# CM4 register map
CPU: CM4 r0p1, selectable endian, MPU, FPU, 4 interrupt priority bits
Registers are 32-bit, read-write, reset 0x0 unless marked. A register's access mark holds for its fields unless they carry their own. Offsets are from the block's base; [hi:lo] are bit positions; {n}, {i} and the like mark numbered series.

## SCB — System Control Block
Base 0xE000ED00
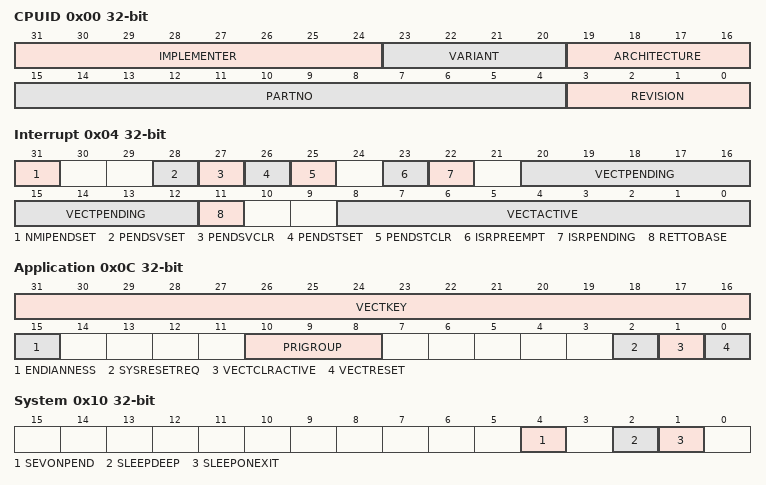
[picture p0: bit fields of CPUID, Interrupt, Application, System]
0x00 CPUID Base Register ro — Provides identification information for the processor
  [31:24] IMPLEMENTER — Implementer code assigned by ARM
  [23:20] VARIANT — IMPLEMENTATION DEFINED variant number
  [19:16] ARCHITECTURE — Reads as 0xF
  [15:4] PARTNO — IMPLEMENTATION DEFINED part number
  [3:0] REVISION — IMPLEMENTATION DEFINED revision number
0x04 Interrupt Control and State Register — Provides software control of the NMI, PendSV, and SysTick exceptions, and provides interrupt status information
  [31] NMIPENDSET write-1-sets — On writes, makes the NMI exception active
    0=cleared (On writes, has no effect. On reads, NMI is inactive); 1=set_pending (On writes, make the NMI exception active. On reads, NMI is active)
  [28] PENDSVSET write-1-sets — On writes, sets the PendSV exception as pending
    0=cleared (On writes, has no effect. On reads, PendSV is not pending); 1=set_pending (On writes, make PendSV exception pending. On reads, PendSV is pending)
  [27] PENDSVCLR write-1-sets — Removes the pending status of the PendSV exception
    0=No effect; 1=clear (Remove pending status)
  [26] PENDSTSET write-1-sets — On writes, sets the SysTick exception as pending
    0=cleared (On writes, has no effect. On reads, SysTick is not pending); 1=set_pending (On writes, make SysTick exception pending. On reads, SysTick is pending)
  [25] PENDSTCLR write-1-sets — Removes the pending status of the SysTick exception
    0=No effect; 1=clear (Remove pending status)
  [23] ISRPREEMPT — Indicates whether a pending exception will be serviced on exit from debug halt state
    0=Will not service; 1=Will service a pending exception
  [22] ISRPENDING — Indicates whether an external interrupt, generated by the NVIC, is pending
    0=No external interrupt pending; 1=External interrupt pending
  [20:12] VECTPENDING — The exception number of the highest priority pending and enabled interrupt
  [11] RETTOBASE — In Handler mode, indicates whether there is an active exception other than the exception indicated by the current value of the IPSR
    0=There is an active exception other than the exception shown by IPSR; 1=There is no active exception other than any exception shown by IPSR
  [8:0] VECTACTIVE — The exception number of the current executing exception
0x08 Vector Table Offset Register — Holds the vector table address
  [31:7] TBLOFF — Bits[31:7] of the vector table address
0x0C Application Interrupt and Reset Control Register — Sets or returns interrupt control data
  [31:16] VECTKEY range 0x05FA..0x05FA — Vector Key. The value 0x05FA must be written to this register.
    0=Do not request a reset; 0x5FA=Request reset
  [15] ENDIANNESS — Indicates the memory system endianness
    0=Little endian; 1=Big endian
  [10:8] PRIGROUP — Priority grouping, indicates the binary point position
  [2] SYSRESETREQ — System Reset Request
    0=Do not request a reset; 1=Request reset
  [1] VECTCLRACTIVE — Writing 1 to this bit clears all active state information for fixed and configurable exceptions
  [0] VECTRESET — Writing 1 to this bit causes a local system reset
0x10 System Control Register — Sets or returns system control data
  [4] SEVONPEND — Determines whether an interrupt transition from inactive state to pending state is a wakeup event
    0=Transitions from inactive to pending are not wakeup events; 1=Transitions from inactive to pending are wakeup events
  [2] SLEEPDEEP — Provides a qualifying hint indicating that waking from sleep might take longer
    0=Selected sleep state is not deep sleep; 1=Selected sleep state is deep sleep
  [1] SLEEPONEXIT — Determines whether, on an exit from an ISR that returns to the base level of execution priority, the processor enters a sleep state
    0=Do not enter sleep state; 1=Enter sleep state
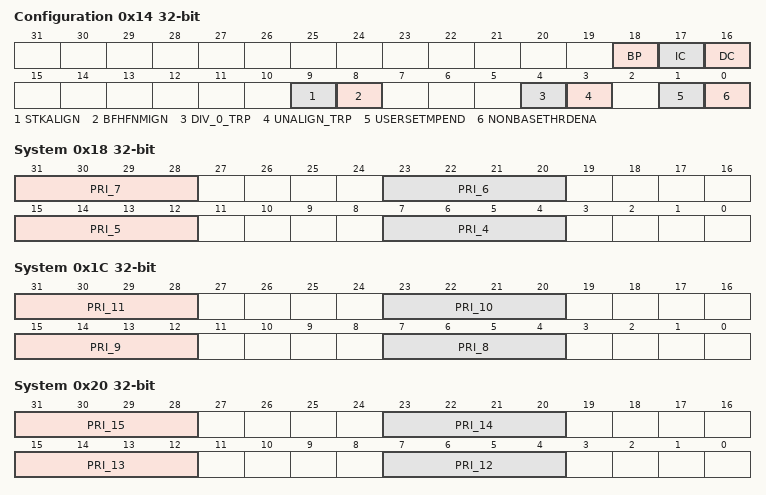
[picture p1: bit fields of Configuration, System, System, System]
0x14 Configuration and Control Register — Sets or returns configuration and control data, and provides control over caching and branch prediction
  [18] BP — Branch prediction enable bit
    0=Program flow prediction disabled; 1=Program flow prediction enabled
  [17] IC — Instruction cache enable bit
    0=Instruction caches disabled; 1=Instruction caches enabled
  [16] DC — Cache enable bit
    0=Data and unified caches disabled; 1=Data and unified caches enabled
  [9] STKALIGN — Determines whether the exception entry sequence guarantees 8-byte stack frame alignment, adjusting the SP if necessary before saving state
    0=Guaranteed SP alignment is 4-byte, no SP adjustment is performed; 1=8-byte alignment guaranteed, SP adjusted if necessary
  [8] BFHFNMIGN — Determines the effect of precise data access faults on handlers running at priority -1 or priority -2
    0=Precise data access fault causes a lockup; 1=Handler ignores the fault
  [4] DIV_0_TRP — Controls the trap on divide by 0
    0=Trapping disabled; 1=Trapping enabled
  [3] UNALIGN_TRP — Controls the trapping of unaligned word or halfword accesses
    0=Trapping disabled; 1=Trapping enabled
  [1] USERSETMPEND — Controls whether unprivileged software can access the STIR
    0=Unprivileged software cannot access the STIR; 1=Unprivileged software can access the STIR
  [0] NONBASETHRDENA — Controls whether the processor can enter Thread mode with exceptions active
    0=Any attempt to enter Thread mode with exceptions active faults; 1=The processor can enter Thread mode with exceptions active because of a controlled return value
0x18 System Handler Priority Register 1 — Sets or returns priority for system handlers 4-7
  [31:28] PRI_7 — Reserved for priority of system handler 7
  [23:20] PRI_6 — Priority of system handler 6, UsageFault
  [15:12] PRI_5 — Priority of system handler 5, BusFault
  [7:4] PRI_4 — Priority of system handler 4, MemManage
0x1C System Handler Priority Register 2 — Sets or returns priority for system handlers 8-11
  [31:28] PRI_11 — Priority of system handler 11, SVCall
  [23:20] PRI_10 — Reserved for priority of system handler 10
  [15:12] PRI_9 — Reserved for priority of system handler 9
  [7:4] PRI_8 — Reserved for priority of system handler 8
0x20 System Handler Priority Register 3 — Sets or returns priority for system handlers 12-15
  [31:28] PRI_15 — Priority of system handler 15, SysTick
  [23:20] PRI_14 — Priority of system handler 14, PendSV
  [15:12] PRI_13 — Reserved for priority of system handler 13
  [7:4] PRI_12 — Priority of system handler 12, DebugMonitor
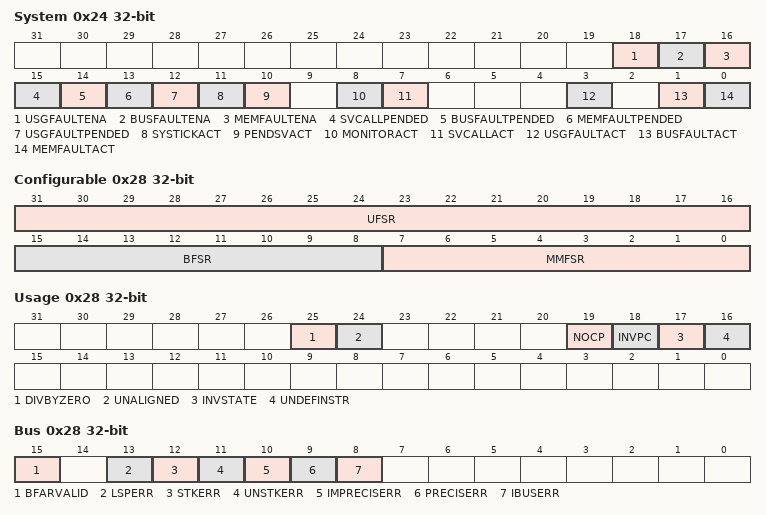
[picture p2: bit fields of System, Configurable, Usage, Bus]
0x24 System Handler Control and State Register — Controls and provides the active and pending status of system exceptions
  [18] USGFAULTENA — UsageFault exception enable
    0=Disable UsageFault; 1=Enable UsageFault
  [17] BUSFAULTENA — BusFault exception enable
    0=Disable BusFault; 1=Enable BusFault
  [16] MEMFAULTENA — MemManage exception enable
    0=Disable MemManage fault; 1=Enable MemManage fault
  [15] SVCALLPENDED — SVCall exception pended state
    0=SVCall execption is not pending; 1=SVCall execption is pending
  [14] BUSFAULTPENDED — BusFault exception pended state
    0=BusFault execption is not pending; 1=BusFault execption is pending
  [13] MEMFAULTPENDED — MemManage exception pended state
    0=MemManage exception is not pending; 1=MemManage exception is pending
  [12] USGFAULTPENDED — UsageFault exception pended state
    0=UsageFault exception is not pending; 1=UsageFault exception is pending
  [11] SYSTICKACT — SysTick exception active state
    0=SysTick exception is not active; 1=SysTick exception is active
  [10] PENDSVACT — PendSV exception active state
    0=PendSV exception is not active; 1=PendSV exception is active
  [8] MONITORACT — DebugMonitor exception active state
    0=DebugMonitor exception not active; 1=DebugMonitor exception is active
  [7] SVCALLACT — SVCall exception active state
    0=SVCall exception is not active; 1=SVCall exception is active
  [3] USGFAULTACT — UsageFault exception active state
    0=UsageFault exception is not active; 1=UsageFault exception is active
  [1] BUSFAULTACT — BusFault exception active state
    0=BusFault exception is not active; 1=BusFault exception is active
  [0] MEMFAULTACT — MemManage exception active state
    0=MemManage exception is not active; 1=MemManage exception is active
0x28 Configurable Fault Status Register — Contains the three Configurable Fault Status Registers
  [31:16] UFSR — Provides information on UsageFault exceptions
  [15:8] BFSR — Provides information on BusFault exceptions
  [7:0] MMFSR — Provides information on MemManage exceptions
0x28 Usage Fault Status Register — Provides information on UsageFault exceptions
  [all] fields
    0=Error has not occurred; 1=Error has occurred
  [25] DIVBYZERO — Divide by zero flag. Indicates whether an integer division by zero error has occurred
  [24] UNALIGNED — Unaligned access flag. Indicates whether an unaligned access error has occurred
  [19] NOCP — No coprocessor flag. Indicates whether a coprocessor disabled or not present error has occurred
  [18] INVPC — Invalid PC flag. Indicates whether an integrity check error has occurred
  [17] INVSTATE — Invalid state flag. Indicates whether an EPSR.T or EPSR.IT validity error has occurred
  [16] UNDEFINSTR — Undefined instruction flag. Indicates whether an undefined instruction error has occurred
0x28 Bus Fault Status Register — Provides information on BusFault exceptions
  [15] BFARVALID — BFAR valid. Indicates validity of the contents of the BFAR register
    0=BFAR content not valid; 1=BFAR content valid
  [13] LSPERR — Lazy state preservation error. Records whether a BusFault occurred during FP lazy state preservation
    0=No BusFault occurred during FP lazy state preservation; 1=BusFault occurred during FP lazy state preservation
  [12] STKERR — Stack error. Records whether a derived BusFault occurred during exception entry stacking
    0=No derived BusFault occurred; 1=Derived BusFault occurred during exception entry
  [11] UNSTKERR — Unstack error. Records whether a derived BusFault occurred during exception return unstacking
    0=No derived BusFault occurred; 1=Derived BusFault occurred during exception return
  [10] IMPRECISERR — Imprecise error. Records whether an imprecise data access error has occurred
    0=No imprecise data access error has occurred; 1=Imprecise data access error has occurred
  [9] PRECISERR — Precise error. Records whether a precise data access error has occurred
    0=No precise data access error has occurred; 1=Precise data access error has occurred
  [8] IBUSERR — Instruction bus error. Records whether a BusFault on an instruction prefetch has occurred
    0=No BusFault on instruction prefetch has occurred; 1=A BusFault on an instruction prefetch has occurred
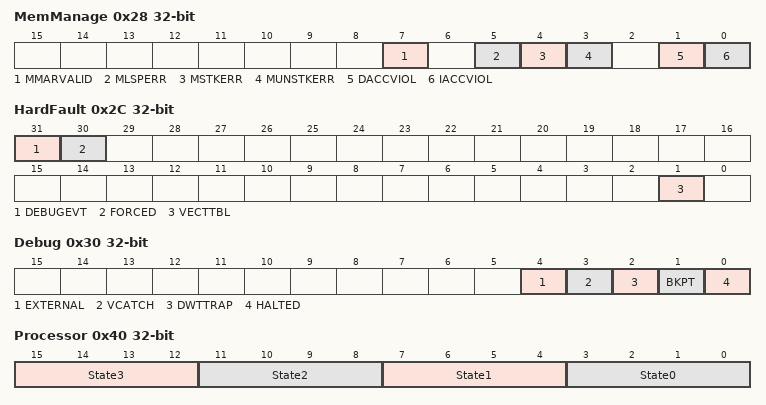
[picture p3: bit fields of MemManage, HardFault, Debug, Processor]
0x28 MemManage Fault Status Register — Provides information on MemManage exceptions
  [7] MMARVALID — MMFAR valid flag. Indicates validity of the MMFAR register
    0=MMFAR content not valid; 1=MMFAR content valid
  [5] MLSPERR — MemManage lazy state preservation error flag. Records whether a MemManage fault occurred during FP lazy state preservation
    0=No MemManage occurred during FP lazy state preservation; 1=MemManage occurred during FP lazy state preservation
  [4] MSTKERR — MemManage stacking error flag. Records whether a derived MemManage fault occurred during exception entry stacking
    0=No derived MemManage occurred; 1=Derived MemManage occurred during exception entry
  [3] MUNSTKERR — MemManage unstacking error flag. Records whether a derived MemManage fault occurred during exception return unstacking
    0=No derived MemManage fault occurred; 1=Derived MemManage fault occurred during exception return
  [1] DACCVIOL — Data access violation flag. Records whether a data access violation has occurred
    0=No MemManage fault on data access has occurred; 1=MemManage fault on data access has occurred
  [0] IACCVIOL — Instruction access violation. Records whether an instruction related memory access violation has occurred
    0=No MemManage fault on instruction access has occurred; 1=MemManage fault on instruction access has occurred
0x2C HardFault Status Register — Shows the cause of any HardFault
  [31] DEBUGEVT — Indicates that a debug event has occurred
    0=No debug event has occurred; 1=Debug event has occurred. The Debug Fault Status Register has been updated
  [30] FORCED — Indicates that a fault with configurable priority has been escalated to a HardFault exception, because it could not be made active, because of priority or because it was disabled
    0=No priority escalation has occurred; 1=Processor has escalated a configurable-priority exception to HardFault
  [1] VECTTBL — Indicates when a fault has occurred because of a vector table read error on exception processing
    0=No vector table read fault has occurred; 1=Vector table read fault has occurred
0x30 Debug Fault Status Register — Shows which debug event occurred
  [all] fields
    0=Debug event has not occurred; 1=Debug event has occurred
  [4] EXTERNAL — External event. Indicates whether an external debug request has occurred
  [3] VCATCH — Vector Catch event. Indicates whether a Vector catch debug event has occurred
  [2] DWTTRAP — Watchpoint event. Indicates whether a Watchpoint debug event has occurred
  [1] BKPT — Breakpoint event. Indicates whether a breakpoint debug event has occurred
  [0] HALTED — Halt or step event. Indicates that a Halt request debug event or Step debug event has occurred
0x34 MemManage Fault Address Register — Shows the address of the memory location that caused an MPU fault
  [31:0] ADDRESS — Address of the memory location that caused the MemManage fault, valid while MMFSR.MMARVALID is set
0x38 BusFault Address Register — Shows the address associated with a precise data access BusFault
  [31:0] ADDRESS — Address of the precise data access BusFault, valid while BFSR.BFARVALID is set
0x3C Auxiliary Fault Status Register — Provides implementation-specific fault status information and control
0x40 Processor Feature Register 0 ro — Gives top-level information about the instruction sets supported by the processor
  [15:12] State3 — ARMv7-M reserved
  [11:8] State2 — ARMv7-M reserved
  [7:4] State1 — Thumb instruction set support
    3=Support for Thumb encoding including Thumb-2 technology, with all basic 16-bit and 32-bit instructions
  [3:0] State0 — ARM instruction set support
    0=The processor does not support the ARM instruction set; 1=ARMv7-M reserved
0x44 Processor Feature Register 1 ro — Gives top-level information about the instruction sets supported by the processor
  [11:8] M profile programmers model
    0=ARMv7-M reserved; 2=Two-stack programmers model supported
0x48 Debug Feature Register 0 ro — Gives top-level information about the debug system used in the processor
  [23:20] Debug model, M profile — Support for memory-mapped debug model for M profile processors
    0=Not supported; 1=Support for M profile Debug architecture, with memory-mapped access
0x4C Auxiliary Feature Register 0 ro — Gives information about the IMPLEMENTATION DEFINED features of a processor implementation
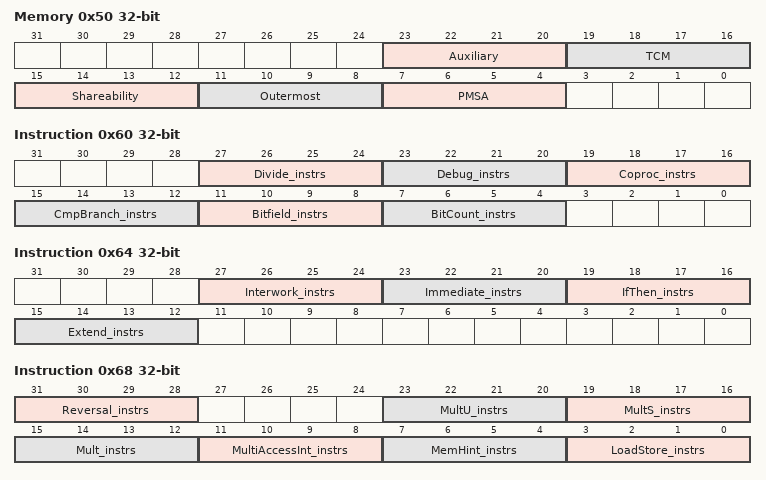
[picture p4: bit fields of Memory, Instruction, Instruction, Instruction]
0x50 Memory Model Feature Register 0 ro — Gives information about the implemented memory model and memory management support
  [23:20] Auxiliary registers — Indicates the support for Auxiliary registers
    0=Not supported; 1=Support for Auxiliary Control Register only; 2=ARMv7-M reserved
  [19:16] TCM support — Indicates the support for Tightly Coupled Memory (TCM)
    0=No tightly coupled memories implemented; 1=Tightly coupled memories implemented with IMPLEMENTATION DEFINED control; 2=ARMv7-M reserved
  [15:12] Shareability levels — Indicates the number of shareability levels implemented
    0=One level of shareability implemented; 1=ARMv7-M reserved
  [11:8] Outermost shareability — Indicates the outermost shareability domain implemented
    0=Implemented as Non-cacheable; 1=ARMv7-M reserved; 15=Shareability ignored
  [7:4] PMSA support — Indicates support for a PMSA
    0=Not supported; 3=PMSAv7, providing support for a base region and subregions
0x54 Memory Model Feature Register 1 ro — Gives information about the implemented memory model and memory management support
0x58 Memory Model Feature Register 2 ro — Gives information about the implemented memory model and memory management support
  [27:24] WFI stall — Indicates the support for Wait For Interrupt (WFI) stalling
    0=Not supported; 1=Support for WFI stalling
0x5C Memory Model Feature Register 3 ro — Gives information about the implemented memory model and memory management support
0x60 Instruction Set Attribute Register 0 ro — Gives information about the instruction sets implemented by the processor
  [27:24] Divide_instrs — Indicates the supported Divide instructions
    0=None supported, ARMv7-M reserved; 1=Adds support for the SDIV and UDIV instructions
  [23:20] Debug_instrs — Indicates the supported Debug instructions
    0=None supported, ARMv7-M reserved; 1=Adds support for the BKPT instruction
  [19:16] Coproc_instrs — Indicates the supported Coprocessor instructions
    0=None supported, except for separately attributed architectures, for example the Floating-point extension; 1=Adds support for generic CDP, LDC, MCR, MRC, and STC instructions; 2=As for 1, and adds support for generic CDP2, LDC2, MCR2, MRC2, and STC2 instructions; 3=As for 2, and adds support for generic MCRR and MRRC instructions, 4 As for 3, and adds support for generic MCRR2 and MRRC2 inst
  [15:12] CmpBranch_instrs — Indicates the supported combined Compare and Branch instructions
    0=None supported, ARMv7-M reserved; 1=Adds support for the CBNZ and CBZ instructions
  [11:8] Bitfield_instrs — Indicates the supported BitField instructions
    0=None supported, ARMv7-M reserved; 1=Adds support for the BFC, BFI, SBFX, and UBFX instructions
  [7:4] BitCount_instrs — Indicates the supported Bit Counting instructions
    0=None supported, ARMv7-M reserved; 1=Adds support for the CLZ instruction
0x64 Instruction Set Attribute Register 1 ro — Gives information about the instruction sets implemented by the processor
  [27:24] Interwork_instrs — Indicates the supported Interworking instructions
    0=None supported, ARMv7-M reserved; 1=Adds support for the BX instruction, and the T bit in the PSR; 2=As for 1, and adds support for the BLX instruction, and PC loads have BX-like behavior; 3=ARMv7-M reserved
  [23:20] Immediate_instrs — Indicates the support for data-processing instructions with long immediates
    0=None supported, ARMv7-M reserved; 1=Adds support for the ADDW, MOVW, MOVT, and SUBW instructions
  [19:16] IfThen_instrs — Indicates the supported IfThen instructions
    0=None supported, ARMv7-M reserved; 1=Adds support for the IT instructions, and for the IT bits in the PSRs
  [15:12] Extend_instrs — Indicates the supported Extend instructions
    0=None supported, ARMv7-M reserved; 1=Adds support for the SXTB, SXTH, UXTB, and UXTH instructions; 2=As for 1, and adds support for the SXTAB, SXTAB16, SXTAH, SXTB16, UXTAB, UXTAB16, UXTAH, and UXTB16 instructions
0x68 Instruction Set Attribute Register 2 ro — Gives information about the instruction sets implemented by the processor
  [31:28] Reversal_instrs — Indicates the supported Reversal instructions
    0=None supported, ARMv7-M reserved; 1=Adds support for the REV, REV16, and REVSH instructions, ARMv7-M reserved; 2=As for 1, and adds support for the RBIT instruction
  [23:20] MultU_instrs — Indicates the supported advanced unsigned Multiply instructions
    0=None supported, ARMv7-M reserved; 1=Adds support for the UMULL and UMLAL instructions; 2=As for 1, and adds support for the UMAAL instruction
  [19:16] MultS_instrs — Indicates the supported advanced signed Multiply instructions
    0=None supported, ARMv7-M reserved; 1=Adds support for the SMULL and SMLAL instructions; 2=As for 1, and adds support for the SMLABB, SMLABT, SMLALBB, SMLALBT, SMLALTB, SMLALTT, SMLATB, SMLATT, SMLAWB, SMLAWT, SMULBB, S; 3=As for 2, and adds support for the SMLAD, SMLADX, SMLALD, SMLALDX, SMLSD, SMLSDX, SMLSLD, SMLSLDX, SMMLA, SMMLAR, SMMLS, SMMLSR,
  [15:12] Mult_instrs — Indicates the supported additional Multiply instructions
    0=None supported. This means only MUL is supported. ARMv7-M reserved; 1=Adds support for the MLA instruction, ARMv7-M reserved; 2=As for 1, and adds support for the MLS instruction
  [11:8] MultiAccessInt_instrs — Indicates the support for multi-access interruptible instructions
    0=None supported. This means the LDM and STM instructions are not interruptible; 1=LDM and STM instructions are restartable; 2=LDM and STM instructions are continuable
  [7:4] MemHint_instrs — Indicates the supported Memory Hint instructions
    0=None supported, ARMv7-M reserved; 2=Adds support for the PLD instruction; 3=As for 1 or 2, and adds support for the PLI instruction
  [3:0] LoadStore_instrs — Indicates the supported additional load and store instructions
    0=None supported, ARMv7-M reserved; 1=Adds support for the LDRD and STRD instructions
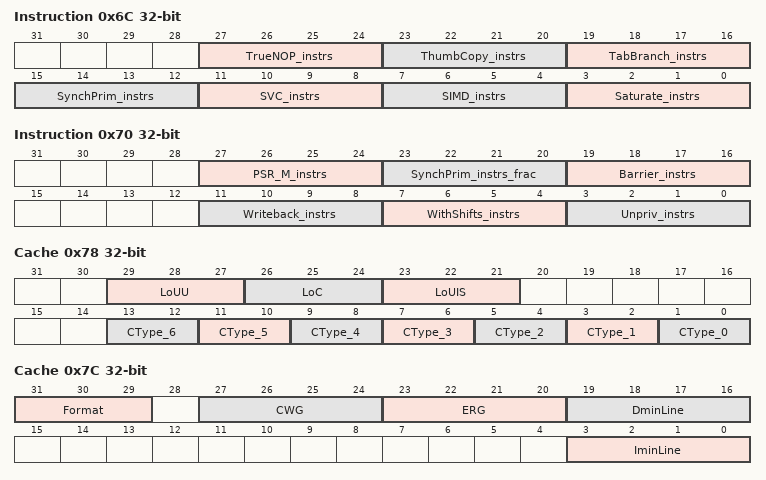
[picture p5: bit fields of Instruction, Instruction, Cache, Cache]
0x6C Instruction Set Attribute Register 3 ro — Gives information about the instruction sets implemented by the processor
  [27:24] TrueNOP_instrs — Indicates the support for a true NOP instruction
    0=None supported, ARMv7-M reserved; 1=Adds support for the true NOP instruction
  [23:20] ThumbCopy_instrs — Indicates the supported non flag-setting MOV instructions
    0=None supported, ARMv7-M reserved; 1=Adds support for encoding T1 of the MOV (register) instruction copying from a low register to a low register
  [19:16] TabBranch_instrs — Indicates the supported Table Branch instructions
    0=None supported, ARMv7-M reserved; 1=Adds support for the TBB and TBH instructions
  [15:12] SynchPrim_instrs — Must be interpreted with the ID_ISAR4
  [11:8] SVC_instrs — Indicates the supported SVC instructions
    0=None supported, ARMv7-M reserved; 1=Adds support for the SVC instruction
  [7:4] SIMD_instrs — Indicates the supported SIMD instructions
    0=None supported, ARMv7-M reserved; 1=Adds support for the SSAT and USAT instructions, and for the Q bit in the PSRs; 3=As for 1, and adds support for the PKHBT, PKHTB, QADD16, QADD8, QASX, QSUB16, QSUB8, QSAX, SADD16, SADD8, SASX, SEL, SHADD16, SH
  [3:0] Saturate_instrs — Indicates the supported Saturate instructions
    0=None supported; 1=Adds support for the QADD, QDADD, QDSUB, and QSUB instructions, and for the Q bit in the PSRs
0x70 Instruction Set Attribute Register 4 ro — Gives information about the instruction sets implemented by the processor
  [27:24] PSR_M_instrs — Indicates the supported M profile instructions to modify the PSRs
    0=None supported, ARMv7-M reserved; 1=Adds support for the M-profile forms of the CPS, MRS, and MSR instructions, to access the PSRs
  [23:20] SynchPrim_instrs_frac — Must be interpreted with the ID_ISAR3
  [19:16] Barrier_instrs — Indicates the supported Barrier instructions
    0=None supported, ARMv7-M reserved; 1=Adds support for the DMB, DSB, and ISB barrier instructions
  [11:8] Writeback_instrs — Indicates the support for Writeback addressing modes
    0=Basic support; 1=Adds support for all of the writeback addressing modes defined in the ARMv7-M architecture
  [7:4] WithShifts_instrs — Indicates the support for instructions with shifts
    0=Nonzero shifts supported only in MOV and shift instructions; 1=Adds support for shifts of loads and stores over the range LSL 0-3; 3=As for 1, and adds support for other constant shift options, on loads, stores, and other instructions; 4=ARMv7-M reserved
  [3:0] Unpriv_instrs — Indicates the supported unprivileged instructions
    0=None supported, ARMv7-M reserved; 1=Adds support for the LDRBT, LDRT, STRBT, and STRT instructions; 2=As for 1, and adds support for the LDRHT, LDRSBT, LDRSHT, and STRHT instructions
0x78 Cache Level ID Register ro — The CLIDR identifies: ? The type of cache, or caches, implemented at each level, up to a maximum of seven levels
  [29:27] LoUU — Level of Unification Uniprocessor for the cache hierarchy
  [26:24] LoC — Level of Coherency for the cache hierarchy
  [23:21] LoUIS — Level of Unification Inner Shareable for the cache hierarchy
  [2n+1:2n] CType_{n} (n=0..6) — Indicates the type of cache implemented at each level
    0=No cache; 1=Instruction cache only; 2=Data cache only; 3=Separate instruction and data caches; 4=Unified cache
0x7C Cache Type Register ro — The CTR provides information about the architecture of the caches
  [31:29] Format — Indicates the implemented CTR format
    4=ARMv7 format. This is the format described in this section
  [27:24] CWG — Cache Write-back Granule
  [23:20] ERG — Exclusives Reservation Granule
  [19:16] DminLine — Log2 of the number of words in the smallest cache line of all the data caches and unified caches that are controlled by the processor
  [3:0] IminLine — Log2 of the number of words in the smallest cache line of all the instruction caches that are controlled by the processor
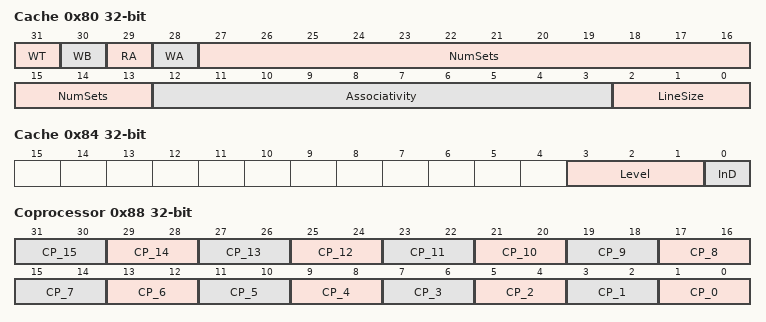
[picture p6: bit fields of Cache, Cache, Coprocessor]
0x80 Cache Size ID Registers ro — The CCSIDR provides information about the architecture of the caches
  [31] WT — Indicates whether the cache level supports write-through
  [30] WB — Indicates whether the cache level supports write-back
  [29] RA — Indicates whether the cache level supports read-allocation
  [28] WA — Indicates whether the cache level supports write-allocation
  [27:13] NumSets — (Number of sets in cache)-1, therefore a value of 0 indicates 1 set in the cache
  [12:3] Associativity — (Associativity of cache)-1, therefore a value of 0 indicates an associativity of 1
  [2:0] LineSize — (Log2(Number of words in cache line))-2
0x84 Cache Size Selection Register ro — The CSSELR selects the current CCSIDR by specifying the required cache level
  [3:1] Level — Cache level of required cache
  [0] InD — Instruction not data bit
    0=Data or unified cache; 1=Instruction cache
0x88 Coprocessor Access Control Register — Specifies the access privileges for coprocessors
  [2n+1:2n] CP_{n} (n=0..15) — for n values 0-7, 10 and 11 Access privileges for coprocessor n
    0=Access denied. Any attempted access generates a NOCP UsageFault; 1=Privileged access only. An unprivileged access generates a NOCP UsageFault; 3=Full access
